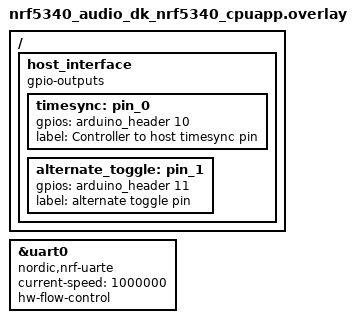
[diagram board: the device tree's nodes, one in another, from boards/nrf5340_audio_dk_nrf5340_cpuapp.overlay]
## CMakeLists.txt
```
# SPDX-License-Identifier: Apache-2.0

cmake_minimum_required(VERSION 3.20.0)

find_package(Zephyr REQUIRED HINTS $ENV{ZEPHYR_BASE})
project(hci_uart)

set(SRCS
    ${CMAKE_CURRENT_SOURCE_DIR}/src/main.c
)

if (CONFIG_ENABLE_AUDIO_TIMESYNC)
    if (CONFIG_SOC_COMPATIBLE_NRF52X)
        target_sources(app PRIVATE src/controller_time_nrf52.c)
    elseif (CONFIG_SOC_COMPATIBLE_NRF5340_CPUAPP)
        target_sources(app PRIVATE src/controller_time_nrf53_app.c)
    elseif (CONFIG_SOC_SERIES_NRF54LX OR CONFIG_SOC_SERIES_NRF54HX)
        target_sources(app PRIVATE src/controller_time_nrf54.c)
    else()
        MESSAGE(FATAL_ERROR "Unsupported series")
    endif()
endif()

target_sources(app PRIVATE ${SRCS})
```

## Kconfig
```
# SPDX-License-Identifier: Apache-2.0

menu "Modules"

config ENABLE_AUDIO_TIMESYNC
    bool "Enables synchronization between the APP and NET core running SD"
    default SOC_SERIES_NRF53X || SOC_NRF52833 || SOC_SERIES_NRF54LX
    select NRFX_RTC0 if SOC_SERIES_NRF53X
    select NRFX_DPPI if SOC_SERIES_NRF53X
    select NRFX_TIMER0 if SOC_SERIES_NRF53X
    select NRFX_RTC2 if SOC_SERIES_NRF52X
    select NRFX_PPI if SOC_SERIES_NRF52X
    select NRFX_TIMER1 if SOC_SERIES_NRF52X
endmenu

module = AUDIO_SYNC_TIMER
module-str = audio-sync-timer

source "subsys/logging/Kconfig.template.log_config"
source "Kconfig.zephyr"
```

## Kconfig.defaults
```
# Audio sync timer
config NRFX_TIMER1
	default y

# Audio sync timer
config NRFX_DPPI
	default y
```

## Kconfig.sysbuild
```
# SPDX-License-Identifier: Apache-2.0

config NRF_DEFAULT_IPC_RADIO
    default y if BOARD_NRF5340DK_NRF5340_CPUAPP || BOARD_NRF5340_AUDIO_DK_NRF5340_CPUAPP || BOARD_THINGY53_NRF5340_CPUAPP || BOARD_THINGY53_NRF5340_CPUAPP_NS || BOARD_NRF54H20DK_NRF54H20_CPUAPP

source "share/sysbuild/Kconfig"
```

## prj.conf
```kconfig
CONFIG_CONSOLE=n
CONFIG_STDOUT_CONSOLE=n
CONFIG_UART_CONSOLE=n
CONFIG_GPIO=y
CONFIG_SERIAL=y
CONFIG_UART_INTERRUPT_DRIVEN=y
CONFIG_BT=y
CONFIG_BT_HCI_RAW=y
CONFIG_BT_HCI_RAW_H4=y
CONFIG_BT_HCI_RAW_H4_ENABLE=y
CONFIG_BT_BUF_ACL_RX_SIZE=255
CONFIG_BT_BUF_CMD_TX_SIZE=255
CONFIG_BT_BUF_EVT_DISCARDABLE_SIZE=255
CONFIG_BT_MAX_CONN=16
#CONFIG_BT_TINYCRYPT_ECC=n

# Setup ISO Buffer
CONFIG_BT_ISO_TX_BUF_COUNT=5
CONFIG_BT_ISO_TX_MTU=251
CONFIG_BT_ISO_RX_BUF_COUNT=5
CONFIG_BT_ISO_RX_MTU=251

# Enable ISO support
CONFIG_BT_ISO_PERIPHERAL=y
CONFIG_BT_ISO_CENTRAL=y
CONFIG_BT_ISO_BROADCASTER=y
CONFIG_BT_ISO_SYNC_RECEIVER=y
CONFIG_BT_EXT_ADV=y
CONFIG_BT_PER_ADV_SYNC_TRANSFER_RECEIVER=y
CONFIG_BT_PER_ADV_SYNC_TRANSFER_SENDER=y

# Support six links as a central, or one link as a peripheral
CONFIG_BT_MAX_CONN=8

# Workaround: Unable to allocate command buffer when using K_NO_WAIT since
# Host number of completed commands does not follow normal flow control.
CONFIG_BT_BUF_CMD_TX_COUNT=10

# for the timesync command
CONFIG_BT_HCI_RAW_CMD_EXT=y
```

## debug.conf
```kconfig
CONFIG_ASSERT=y

#CONFIG_THREAD_NAME=y
#CONFIG_THREAD_ANALYZER=y
#CONFIG_THREAD_ANALYZER_AUTO=y
#CONFIG_THREAD_ANALYZER_RUN_UNLOCKED=y

CONFIG_HW_STACK_PROTECTION=y

CONFIG_CONSOLE=y
CONFIG_LOG=y
CONFIG_LOG_BUFFER_SIZE=4096
CONFIG_RTT_CONSOLE=y
CONFIG_LOG_BACKEND_RTT=y
CONFIG_LOG_BACKEND_RTT_MODE_DROP=n
CONFIG_USE_SEGGER_RTT=y
CONFIG_SEGGER_RTT_BUFFER_SIZE_UP=4096
CONFIG_LOG_BACKEND_SHOW_COLOR=n
CONFIG_LOG_PROCESS_THREAD_STACK_SIZE=1024

CONFIG_LOG_DEFAULT_LEVEL=3

CONFIG_DEBUG_OPTIMIZATIONS=y
CONFIG_DEBUG_INFO=y
```

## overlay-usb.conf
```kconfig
#USB stuff
CONFIG_USB_DEVICE_STACK=y
CONFIG_USB_DEVICE_PRODUCT="Zephyr HCI UART sample"
CONFIG_USB_CDC_ACM=y
CONFIG_USB_DEVICE_INITIALIZE_AT_BOOT=n

#CONFIG_USB_DEVICE_LOG_LEVEL_DBG=y

# stack
#CONFIG_ISR_STACK_SIZE=8192
#CONFIG_IDLE_STACK_SIZE=8192
#CONFIG_MAIN_STACK_SIZE=8192
#CONFIG_SYSTEM_WORKQUEUE_STACK_SIZE=8192
#CONFIG_IPC_SERVICE_BACKEND_RPMSG_WQ_STACK_SIZE=8192
#CONFIG_HEAP_MEM_POOL_SIZE=8192

#debug stuff
#CONFIG_ASSERT=y

#CONFIG_THREAD_NAME=y
#CONFIG_THREAD_ANALYZER=y
#CONFIG_THREAD_ANALYZER_AUTO=y
#CONFIG_THREAD_ANALYZER_RUN_UNLOCKED=y

#CONFIG_HW_STACK_PROTECTION=y

#CONFIG_CONSOLE=n
#CONFIG_LOG=y
#CONFIG_LOG_BUFFER_SIZE=4096
#CONFIG_RTT_CONSOLE=y
#CONFIG_UART_CONSOLE=n
#CONFIG_LOG_BACKEND_RTT=y
#CONFIG_LOG_BACKEND_RTT_MODE_DROP=n
#CONFIG_USE_SEGGER_RTT=y
#CONFIG_SEGGER_RTT_BUFFER_SIZE_UP=2048
#CONFIG_LOG_BACKEND_SHOW_COLOR=n
#CONFIG_LOG_PROCESS_THREAD_STACK_SIZE=8192

#CONFIG_LOG_DEFAULT_LEVEL=3
```

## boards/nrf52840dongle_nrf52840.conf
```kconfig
CONFIG_BOOTLOADER_MCUBOOT=y
```

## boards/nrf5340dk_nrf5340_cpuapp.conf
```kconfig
# timesync
CONFIG_NRFX_TIMER0=y
CONFIG_NRFX_RTC0=y
#CONFIG_NRFX_PPI=y
```

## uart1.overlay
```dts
&gpio_fwd {
    status = "disabled";
};

&uart1 {
    compatible = "nordic,nrf-uarte";
    status = "okay";
    current-speed = <1000000>;
    hw-flow-control;
};

/ {
	chosen {
		zephyr,bt-c2h-uart = &uart1;
	};
};
```

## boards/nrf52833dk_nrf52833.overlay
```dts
/*
 * Copyright (c) 2022 Nordic Semiconductor ASA
 *
 * SPDX-License-Identifier: Apache-2.0
 */

/ {
	host_interface {
		compatible = "gpio-outputs";
		status = "okay";
		timesync: pin_0 {
			gpios = <&gpio1 01 GPIO_ACTIVE_HIGH>;
			label = "Controller to host timesync pin";
		};
	};
};

 &uart0 {
	compatible = "nordic,nrf-uarte";
	current-speed = <1000000>;
	status = "okay";
	hw-flow-control;
};
```

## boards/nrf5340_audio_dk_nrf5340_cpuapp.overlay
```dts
/ {
    host_interface {
        compatible = "gpio-outputs";
        status = "okay";
        timesync: pin_0 {
		    gpios = <&arduino_header 10 GPIO_ACTIVE_HIGH>;
            label = "Controller to host timesync pin";
        };
        alternate_toggle: pin_1 {
		    gpios = <&arduino_header 11 GPIO_ACTIVE_HIGH>;
            label = "alternate toggle pin";
        };
   };
};

&uart0 {
	compatible = "nordic,nrf-uarte";
	current-speed = <1000000>;
	status = "okay";
	hw-flow-control;
};
```

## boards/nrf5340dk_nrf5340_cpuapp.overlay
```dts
/* SPDX-License-Identifier: Apache-2.0 */

/ {
    host_interface {
        compatible = "gpio-outputs";
        status = "okay";
        timesync: pin_0 {
		    gpios = <&arduino_header 10 GPIO_ACTIVE_HIGH>;
            label = "Controller to host timesync pin";
        };
    };
};

&uart0 {
	compatible = "nordic,nrf-uarte";
	current-speed = <1000000>;
	status = "okay";
	hw-flow-control;
};
```

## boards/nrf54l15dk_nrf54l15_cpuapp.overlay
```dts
/*
 * Copyright (c) 2024 Nordic Semiconductor ASA
 *
 * SPDX-License-Identifier: Apache-2.0
 */

/ {
	host_interface {
		compatible = "gpio-outputs";
		status = "okay";
		timesync: pin_0 {
			gpios = <&gpio1 11 GPIO_ACTIVE_HIGH>;
			label = "Controller to host timesync pin";
		};
	};
};

&uart20 {
	compatible = "nordic,nrf-uarte";
	current-speed = <1000000>;
	status = "okay";
	hw-flow-control;
};
```

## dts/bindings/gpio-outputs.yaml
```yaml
description: |
    This is for general gpio support

compatible: "gpio-outputs"

child-binding:
    description: GPIO output child node
    properties:
       gpios:
          type: phandle-array
          required: true
          description: port pin description
       label:
          required: false
          type: string
          description: |
            Human readable string describing the pin. It can be used by an
            application to identify this pin or to retrieve its number/index
            (i.e. child node number) on the parent device.
```

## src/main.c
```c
/*
 * Copyright (c) 2016 Nordic Semiconductor ASA
 * Copyright (c) 2015-2016 Intel Corporation
 *
 * SPDX-License-Identifier: Apache-2.0
 */

#include <errno.h>
#include <stddef.h>
#include <stdio.h>
#include <string.h>

#include <zephyr/kernel.h>
#include <zephyr/arch/cpu.h>
#include <zephyr/sys/byteorder.h>
#include <zephyr/logging/log.h>
#include <zephyr/sys/util.h>

#include <zephyr/device.h>
#include <zephyr/init.h>
#include <zephyr/drivers/uart.h>
//#include <zephyr/drivers/bluetooth/hci_driver.h>
#include <zephyr/drivers/gpio.h>

#include <zephyr/usb/usb_device.h>

#include <zephyr/net_buf.h>
#include <zephyr/bluetooth/bluetooth.h>
#include <zephyr/bluetooth/l2cap.h>
#include <zephyr/bluetooth/hci.h>
#include <zephyr/bluetooth/buf.h>
#include <zephyr/bluetooth/hci_raw.h>

// nRF54L15 - from ncs/nrf/samples/bluetooth/conn_time_sync
#include "controller_time.h"

#define LOG_MODULE_NAME hci_uart
LOG_MODULE_REGISTER(LOG_MODULE_NAME);

static const struct device *const hci_uart_dev =
	DEVICE_DT_GET(DT_CHOSEN(zephyr_bt_c2h_uart));
static K_THREAD_STACK_DEFINE(tx_thread_stack, CONFIG_BT_HCI_TX_STACK_SIZE);
static struct k_thread tx_thread_data;
static K_FIFO_DEFINE(tx_queue);

/* RX in terms of bluetooth communication */
static K_FIFO_DEFINE(uart_tx_queue);

#define H4_CMD 0x01
#define H4_ACL 0x02
#define H4_SCO 0x03
#define H4_EVT 0x04
#define H4_ISO 0x05

/* Receiver states. */
#define ST_IDLE 0	/* Waiting for packet type. */
#define ST_HDR 1	/* Receiving packet header. */
#define ST_PAYLOAD 2	/* Receiving packet payload. */
#define ST_DISCARD 3	/* Dropping packet. */

/* Length of a discard/flush buffer.
 * This is sized to align with a BLE HCI packet:
 * 1 byte H:4 header + 32 bytes ACL/event data
 * Bigger values might overflow the stack since this is declared as a local
 * variable, smaller ones will force the caller to call into discard more
 * often.
 */
#define H4_DISCARD_LEN 33

static int h4_read(const struct device *uart, uint8_t *buf, size_t len)
{
	int rx = uart_fifo_read(uart, buf, len);

	LOG_DBG("read %d req %d", rx, len);

	return rx;
}

static bool valid_type(uint8_t type)
{
	return (type == H4_CMD) | (type == H4_ACL) | (type == H4_ISO);
}

/* Function expects that type is validated and only CMD, ISO or ACL will be used. */
static uint32_t get_len(const uint8_t *hdr_buf, uint8_t type)
{
	switch (type) {
	case H4_CMD:
		return ((const struct bt_hci_cmd_hdr *)hdr_buf)->param_len;
	case H4_ISO:
		return bt_iso_hdr_len(
			sys_le16_to_cpu(((const struct bt_hci_iso_hdr *)hdr_buf)->len));
	case H4_ACL:
		return sys_le16_to_cpu(((const struct bt_hci_acl_hdr *)hdr_buf)->len);
	default:
		LOG_ERR("Invalid type: %u", type);
		return 0;
	}
}

/* Function expects that type is validated and only CMD, ISO or ACL will be used. */
static int hdr_len(uint8_t type)
{
	switch (type) {
	case H4_CMD:
		return sizeof(struct bt_hci_cmd_hdr);
	case H4_ISO:
		return sizeof(struct bt_hci_iso_hdr);
	case H4_ACL:
		return sizeof(struct bt_hci_acl_hdr);
	default:
		LOG_ERR("Invalid type: %u", type);
		return 0;
	}
}

static void rx_isr(void)
{
	static struct net_buf *buf;
	static int remaining;
	static uint8_t state;
	static uint8_t type;
	static uint8_t hdr_buf[MAX(sizeof(struct bt_hci_cmd_hdr),
			sizeof(struct bt_hci_acl_hdr))];
	int read;

	do {
		switch (state) {
		case ST_IDLE:
			/* Get packet type */
			read = h4_read(hci_uart_dev, &type, sizeof(type));
			/* since we read in loop until no data is in the fifo,
			 * it is possible that read = 0.
			 */
			if (read) {
				if (valid_type(type)) {
					/* Get expected header size and switch
					 * to receiving header.
					 */
					remaining = hdr_len(type);
					state = ST_HDR;
				} else {
					LOG_WRN("Unknown header %d", type);
				}
			}
			break;
		case ST_HDR:
			read = h4_read(hci_uart_dev,
				       &hdr_buf[hdr_len(type) - remaining],
				       remaining);
			remaining -= read;
			if (remaining == 0) {
				/* Header received. Allocate buffer and get
				 * payload length. If allocation fails leave
				 * interrupt. On failed allocation state machine
				 * is reset.
				 */
				buf = bt_buf_get_tx(BT_BUF_H4, K_NO_WAIT,
						    &type, sizeof(type));
				if (!buf) {
					LOG_ERR("No available command buffers!");
					state = ST_IDLE;
					return;
				}

				remaining = get_len(hdr_buf, type);

				net_buf_add_mem(buf, hdr_buf, hdr_len(type));
				if (remaining > net_buf_tailroom(buf)) {
					LOG_ERR("Not enough space in buffer");
					net_buf_unref(buf);
					state = ST_DISCARD;
				} else {
					state = ST_PAYLOAD;
				}

			}
			break;
		case ST_PAYLOAD:
			read = h4_read(hci_uart_dev, net_buf_tail(buf),
				       remaining);
			buf->len += read;
			remaining -= read;
			if (remaining == 0) {
				/* Packet received */
				LOG_DBG("putting RX packet in queue.");
				k_fifo_put(&tx_queue, buf);
				state = ST_IDLE;
			}
			break;
		case ST_DISCARD:
		{
			uint8_t discard[H4_DISCARD_LEN];
			size_t to_read = MIN(remaining, sizeof(discard));

			read = h4_read(hci_uart_dev, discard, to_read);
			remaining -= read;
			if (remaining == 0) {
				state = ST_IDLE;
			}

			break;

		}
		default:
			read = 0;
			__ASSERT_NO_MSG(0);
			break;

		}
	} while (read);
}

static void tx_isr(void)
{
	static struct net_buf *buf;
	int len;

	if (!buf) {
		buf = k_fifo_get(&uart_tx_queue, K_NO_WAIT);
		if (!buf) {
			uart_irq_tx_disable(hci_uart_dev);
			return;
		}
	}

	len = uart_fifo_fill(hci_uart_dev, buf->data, buf->len);
	net_buf_pull(buf, len);
	if (!buf->len) {
		net_buf_unref(buf);
		buf = NULL;
	}
}

static void bt_uart_isr(const struct device *unused, void *user_data)
{
	ARG_UNUSED(unused);
	ARG_UNUSED(user_data);

	if (!(uart_irq_rx_ready(hci_uart_dev) ||
	      uart_irq_tx_ready(hci_uart_dev))) {
		LOG_DBG("spurious interrupt");
	}

	if (uart_irq_tx_ready(hci_uart_dev)) {
		tx_isr();
	}

	if (uart_irq_rx_ready(hci_uart_dev)) {
		rx_isr();
	}
}

static void tx_thread(void *p1, void *p2, void *p3)
{
	while (1) {
		struct net_buf *buf;
		int err;

		/* Wait until a buffer is available */
		buf = k_fifo_get(&tx_queue, K_FOREVER);
		/* Pass buffer to the stack */
		err = bt_send(buf);
        if (err!=BT_HCI_ERR_SUCCESS) {
            if (err!=BT_HCI_ERR_EXT_HANDLED) {
                LOG_ERR("Unable to send (err %d)", err);
            }
            net_buf_unref(buf);
        }

		/* Give other threads a chance to run if tx_queue keeps getting
		 * new data all the time.
		 */
		k_yield();
	}
}

static int h4_send(struct net_buf *buf)
{
	LOG_DBG("buf %p type %u len %u", buf, bt_buf_get_type(buf),
		    buf->len);

	k_fifo_put(&uart_tx_queue, buf);
	uart_irq_tx_enable(hci_uart_dev);

	return 0;
}

#if defined(CONFIG_BT_CTLR_ASSERT_HANDLER)
void bt_ctlr_assert_handle(char *file, uint32_t line)
{
	uint32_t len = 0U, pos = 0U;

	/* Disable interrupts, this is unrecoverable */
	(void)irq_lock();

	uart_irq_rx_disable(hci_uart_dev);
	uart_irq_tx_disable(hci_uart_dev);

	if (file) {
		while (file[len] != '\0') {
			if (file[len] == '/') {
				pos = len + 1;
			}
			len++;
		}
		file += pos;
		len -= pos;
	}

	uart_poll_out(hci_uart_dev, H4_EVT);
	/* Vendor-Specific debug event */
	uart_poll_out(hci_uart_dev, 0xff);
	/* 0xAA + strlen + \0 + 32-bit line number */
	uart_poll_out(hci_uart_dev, 1 + len + 1 + 4);
	uart_poll_out(hci_uart_dev, 0xAA);

	if (len) {
		while (*file != '\0') {
			uart_poll_out(hci_uart_dev, *file);
			file++;
		}
		uart_poll_out(hci_uart_dev, 0x00);
	}

	uart_poll_out(hci_uart_dev, line >> 0 & 0xff);
	uart_poll_out(hci_uart_dev, line >> 8 & 0xff);
	uart_poll_out(hci_uart_dev, line >> 16 & 0xff);
	uart_poll_out(hci_uart_dev, line >> 24 & 0xff);

	while (1) {
	}
}
#endif /* CONFIG_BT_CTLR_ASSERT_HANDLER */

static int hci_uart_init(void)
{
	LOG_DBG("");

	if (IS_ENABLED(CONFIG_USB_CDC_ACM)) {
		if (usb_enable(NULL)) {
			LOG_ERR("Failed to enable USB");
			return -EINVAL;
		}
	}

	if (!device_is_ready(hci_uart_dev)) {
		LOG_ERR("HCI UART %s is not ready", hci_uart_dev->name);
		return -EINVAL;
	}

	uart_irq_rx_disable(hci_uart_dev);
	uart_irq_tx_disable(hci_uart_dev);

	uart_irq_callback_set(hci_uart_dev, bt_uart_isr);

	uart_irq_rx_enable(hci_uart_dev);

	return 0;
}

SYS_INIT(hci_uart_init, APPLICATION, CONFIG_KERNEL_INIT_PRIORITY_DEVICE);

#if defined(CONFIG_ENABLE_AUDIO_TIMESYNC)

#define TIMESYNC_GPIO  DT_NODELABEL(timesync)

#if DT_NODE_HAS_STATUS(TIMESYNC_GPIO, okay)
static const struct gpio_dt_spec timesync_pin = GPIO_DT_SPEC_GET(TIMESYNC_GPIO, gpios);
#else
#error "No timesync gpio available!"
#endif

#define  HCI_CMD_ISO_TIMESYNC	(0x200)

struct hci_cmd_iso_timestamp_response {
    struct bt_hci_evt_cc_status cc;
    uint32_t timestamp;
} __packed;

uint8_t hci_cmd_iso_timesync_cb(struct net_buf *buf)
{
	struct net_buf *rsp;
    struct hci_cmd_iso_timestamp_response *response;

	LOG_INF("buf %p type %u len %u", buf, bt_buf_get_type(buf), buf->len);
	LOG_INF("buf[0] = 0x%02x", buf->data[0]);

	uint32_t timestamp_second_us = 0;

	// Lock interrupts to avoid interrupt between time capture and gpio toggle
	uint32_t key = arch_irq_lock();

#if defined(CONFIG_SOC_SERIES_NRF54LX) || defined(CONFIG_SOC_SERIES_NRF52X) || defined(CONFIG_SOC_SERIES_NRF53X)
	timestamp_second_us = (uint32_t) controller_time_us_get();
#else
    #error selected SoC is not supported yet
#endif

#if DT_NODE_HAS_STATUS(TIMESYNC_GPIO, okay)
	// raise
	gpio_pin_set_dt( &timesync_pin, 1 );
#endif

	// Unlock interrupts
	arch_irq_unlock(key);

	// emit event
	rsp = bt_hci_cmd_complete_create(BT_OP(BT_OGF_VS, HCI_CMD_ISO_TIMESYNC), sizeof(*response));
	response = net_buf_add(rsp, sizeof(*response));
	response->cc.status = BT_HCI_ERR_SUCCESS;
	response->timestamp = timestamp_second_us;

	if (IS_ENABLED(CONFIG_BT_HCI_RAW_H4)) {
		net_buf_push_u8(rsp, H4_EVT);
	}

    h4_send( rsp );

#if DT_NODE_HAS_STATUS(TIMESYNC_GPIO, okay)
	gpio_pin_set_dt( &timesync_pin, 0 );
#endif

	return BT_HCI_ERR_EXT_HANDLED;
}
#endif

int main(void)
{
	/* incoming events and data from the controller */
	static K_FIFO_DEFINE(rx_queue);
	int err;

	LOG_DBG("Start");
	__ASSERT(hci_uart_dev, "UART device is NULL");

	/* Enable the raw interface, this will in turn open the HCI driver */
	bt_enable_raw(&rx_queue);

	if (IS_ENABLED(CONFIG_BT_WAIT_NOP)) {
		/* Issue a Command Complete with NOP */
		int i;

		const struct {
			const uint8_t h4;
			const struct bt_hci_evt_hdr hdr;
			const struct bt_hci_evt_cmd_complete cc;
		} __packed cc_evt = {
			.h4 = H4_EVT,
			.hdr = {
				.evt = BT_HCI_EVT_CMD_COMPLETE,
				.len = sizeof(struct bt_hci_evt_cmd_complete),
			},
			.cc = {
				.ncmd = 1,
				.opcode = sys_cpu_to_le16(BT_OP_NOP),
			},
		};

		for (i = 0; i < sizeof(cc_evt); i++) {
			uart_poll_out(hci_uart_dev,
				      *(((const uint8_t *)&cc_evt)+i));
		}
	}

#if defined(CONFIG_ENABLE_AUDIO_TIMESYNC)
	/* Register iso_timesync command */
	static struct bt_hci_raw_cmd_ext cmd_list = {
	    .op = BT_OP(BT_OGF_VS, HCI_CMD_ISO_TIMESYNC),
		.min_len = 1,
		.func = hci_cmd_iso_timesync_cb
	};

#if DT_NODE_HAS_STATUS(TIMESYNC_GPIO, okay)
	gpio_pin_configure_dt(&timesync_pin, GPIO_OUTPUT_INACTIVE);
#endif

	bt_hci_raw_cmd_ext_register(&cmd_list, 1);
#endif

	/* Spawn the TX thread and start feeding commands and data to the
	 * controller
	 */
	k_thread_create(&tx_thread_data, tx_thread_stack,
			K_THREAD_STACK_SIZEOF(tx_thread_stack), tx_thread,
			NULL, NULL, NULL, K_PRIO_COOP(7), 0, K_NO_WAIT);
	k_thread_name_set(&tx_thread_data, "HCI uart TX");

#if 0
    while (1) {
		uint8_t c = 'A';
		uart_fifo_fill(hci_uart_dev, &c, 1);
		uart_irq_tx_enable(hci_uart_dev);
		k_sleep( K_MSEC(100) );
	}
    return 0;
#endif

    while (1) {
		struct net_buf *buf;

		buf = k_fifo_get(&rx_queue, K_FOREVER);
		err = h4_send(buf);
		if (err) {
			LOG_ERR("Failed to send");
		}
	}
	return 0;
}
```

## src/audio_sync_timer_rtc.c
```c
/*
 * Copyright (c) 2023 Nordic Semiconductor ASA
 *
 * SPDX-License-Identifier: LicenseRef-Nordic-5-Clause
 */

#include "audio_sync_timer.h"

#include <zephyr/kernel.h>
#include <zephyr/init.h>
#include <nrfx_dppi.h>
#include <nrfx_ipc.h>
#include <nrfx_rtc.h>
#include <nrfx_timer.h>
#include <nrfx_egu.h>

#include <zephyr/logging/log.h>
LOG_MODULE_REGISTER(audio_sync_timer, CONFIG_AUDIO_SYNC_TIMER_LOG_LEVEL);

#define AUDIO_SYNC_TIMER_NET_APP_IPC_EVT_CHANNEL                4
#define AUDIO_SYNC_TIMER_NET_APP_IPC_EVT                        NRF_IPC_EVENT_RECEIVE_4

#define AUDIO_SYNC_HF_TIMER_INSTANCE_NUMBER                     1

#define AUDIO_SYNC_HF_TIMER_CURR_TIME_CAPTURE_CHANNEL           1
#define AUDIO_SYNC_HF_TIMER_CURR_TIME_CAPTURE                   NRF_TIMER_TASK_CAPTURE1

static const nrfx_timer_t audio_sync_hf_timer_instance =
	NRFX_TIMER_INSTANCE(AUDIO_SYNC_HF_TIMER_INSTANCE_NUMBER);

#define AUDIO_SYNC_LF_TIMER_INSTANCE_NUMBER                     0

#define AUDIO_SYNC_LF_TIMER_CURR_TIME_CAPTURE_CHANNEL           1
#define AUDIO_SYNC_LF_TIMER_CURR_TIME_CAPTURE                   NRF_RTC_TASK_CAPTURE_1

static uint8_t dppi_channel_curr_time_capture;

static const nrfx_rtc_config_t rtc_cfg = NRFX_RTC_DEFAULT_CONFIG;

static const nrfx_rtc_t audio_sync_lf_timer_instance =
	NRFX_RTC_INSTANCE(AUDIO_SYNC_LF_TIMER_INSTANCE_NUMBER);

static uint8_t dppi_channel_timer_sync_with_rtc;
static uint8_t dppi_channel_rtc_start;
static volatile uint32_t num_rtc_overflows;

static nrfx_timer_config_t cfg = {.frequency = NRFX_MHZ_TO_HZ(1UL),
				  .mode = NRF_TIMER_MODE_TIMER,
				  .bit_width = NRF_TIMER_BIT_WIDTH_32,
				  .interrupt_priority = NRFX_TIMER_DEFAULT_CONFIG_IRQ_PRIORITY,
				  .p_context = NULL};

static uint32_t timestamp_from_rtc_and_timer_get(uint32_t ticks, uint32_t remainder_us)
{
	const uint64_t rtc_ticks_in_femto_units = 30517578125UL;
	const uint32_t rtc_overflow_time_us = 512000000UL;

	return ((ticks * rtc_ticks_in_femto_units) / 1000000000UL) +
		(num_rtc_overflows * rtc_overflow_time_us) +
		remainder_us;
}

uint32_t audio_sync_timer_capture(void)
{
	/* Ensure that the follow product specification statement is handled:
	 *
	 * There is a delay of 6 PCLK16M periods from when the TASKS_CAPTURE[n] is triggered
	 * until the corresponding CC[n] register is updated.
	 *
	 * Lets have a stale value in the CC[n] register and compare that it is different when
	 * we capture using DPPI.
	 *
	 * We ensure it is stale by setting it as the previous tick relative to current
	 * counter value.
	 */
	uint32_t tick_stale = nrf_rtc_counter_get(audio_sync_lf_timer_instance.p_reg);

	/* Set a stale value in the CC[n] register */
	tick_stale--;
	nrf_rtc_cc_set(audio_sync_lf_timer_instance.p_reg,
		       AUDIO_SYNC_LF_TIMER_CURR_TIME_CAPTURE_CHANNEL, tick_stale);

	/* Trigger EGU task to capture RTC and TIMER value */
	nrf_egu_task_trigger(NRF_EGU0, NRF_EGU_TASK_TRIGGER0);

	/* Read captured RTC value */
	uint32_t tick = nrf_rtc_cc_get(audio_sync_lf_timer_instance.p_reg,
				       AUDIO_SYNC_LF_TIMER_CURR_TIME_CAPTURE_CHANNEL);

	/* If required, wait until CC[n] register is updated */
	while (tick == tick_stale) {
		tick = nrf_rtc_cc_get(audio_sync_lf_timer_instance.p_reg,
				      AUDIO_SYNC_LF_TIMER_CURR_TIME_CAPTURE_CHANNEL);
	}

	/* Read captured TIMER value */
	uint32_t remainder_us = nrf_timer_cc_get(NRF_TIMER1,
						 AUDIO_SYNC_HF_TIMER_CURR_TIME_CAPTURE_CHANNEL);

	return timestamp_from_rtc_and_timer_get(tick, remainder_us);
}


//#include <stdio.h>
//#include "led.h"

//bool led_status = false;
static void unused_timer_isr_handler(nrf_timer_event_t event_type, void *p_context)
{
	ARG_UNUSED(event_type);
	ARG_UNUSED(p_context);
#if 0
    if(event_type == NRF_TIMER_EVENT_COMPARE2)
    {
        if( led_status ){
            led_off( LED_APP_3_GREEN );
            led_status = false;
        } else {
            led_on( LED_APP_3_GREEN );
            led_status = true;
        }
//        char * p_msg = p_context;
//        uint32_t remainder_us = nrf_timer_cc_get(NRF_TIMER1,
//						 AUDIO_SYNC_HF_TIMER_CURR_TIME_CAPTURE_CHANNEL);
//        LOG_INF("%d\n", remainder_us );
//        printf("Timer finished. Context passed to the handler: >%s<", p_msg);
    }
#endif
}

static void rtc_isr_handler(nrfx_rtc_int_type_t int_type)
{
	if (int_type == NRFX_RTC_INT_OVERFLOW) {
		num_rtc_overflows++;
	}
}

/**
 * @brief Initialize audio sync timer
 *
 * @note The audio sync timers is replicating the controller's clock.
 * The controller starts or clears the sync timer using a PPI signal
 * sent from the controller. This makes the two clocks synchronized.
 *
 * @return 0 if successful, error otherwise
 */
static int audio_sync_timer_init(void)
{
	nrfx_err_t ret;

	ret = nrfx_timer_init(&audio_sync_hf_timer_instance, &cfg, unused_timer_isr_handler);
	if (ret - NRFX_ERROR_BASE_NUM) {
		LOG_ERR("nrfx timer init error: %d", ret);
		return -ENODEV;
	}

	ret = nrfx_rtc_init(&audio_sync_lf_timer_instance, &rtc_cfg, rtc_isr_handler);
	if (ret - NRFX_ERROR_BASE_NUM) {
		LOG_ERR("nrfx rtc init error: %d", ret);
		return -ENODEV;
	}

	IRQ_CONNECT(RTC0_IRQn, IRQ_PRIO_LOWEST, nrfx_rtc_0_irq_handler, NULL, 0);
	nrfx_rtc_overflow_enable(&audio_sync_lf_timer_instance, true);

	/* Initialize capturing of current timestamps */
	ret = nrfx_dppi_channel_alloc(&dppi_channel_curr_time_capture);
	if (ret - NRFX_ERROR_BASE_NUM) {
		LOG_ERR("nrfx DPPI channel alloc error (current time capture) - Return value: %d", ret);
		return -ENOMEM;
	}

	nrf_rtc_subscribe_set(audio_sync_lf_timer_instance.p_reg,
			      AUDIO_SYNC_LF_TIMER_CURR_TIME_CAPTURE,
			      dppi_channel_curr_time_capture);

	nrf_timer_subscribe_set(audio_sync_hf_timer_instance.p_reg,
				AUDIO_SYNC_HF_TIMER_CURR_TIME_CAPTURE,
				dppi_channel_curr_time_capture);

	nrf_egu_publish_set(NRF_EGU0, NRF_EGU_EVENT_TRIGGERED0, dppi_channel_curr_time_capture);

	ret = nrfx_dppi_channel_enable(dppi_channel_curr_time_capture);
	if (ret - NRFX_ERROR_BASE_NUM) {
		LOG_ERR("nrfx DPPI channel enable error (current time capture) - Return value: %d", ret);
		return -EIO;
	}

	/* Initialize functionality for synchronization between APP and NET core */
	ret = nrfx_dppi_channel_alloc(&dppi_channel_rtc_start);
	if (ret - NRFX_ERROR_BASE_NUM) {
		LOG_ERR("nrfx DPPI channel alloc error (timer clear): %d", ret);
		return -ENOMEM;
	}

	nrf_rtc_subscribe_set(audio_sync_lf_timer_instance.p_reg, NRF_RTC_TASK_CLEAR,
			      dppi_channel_rtc_start);
	nrf_timer_subscribe_set(audio_sync_hf_timer_instance.p_reg, NRF_TIMER_TASK_START,
				dppi_channel_rtc_start);

	nrf_ipc_receive_config_set(NRF_IPC, AUDIO_SYNC_TIMER_NET_APP_IPC_EVT_CHANNEL,
				   NRF_IPC_CHANNEL_4);
	nrf_ipc_publish_set(NRF_IPC, AUDIO_SYNC_TIMER_NET_APP_IPC_EVT, dppi_channel_rtc_start);

	ret = nrfx_dppi_channel_enable(dppi_channel_rtc_start);
	if (ret - NRFX_ERROR_BASE_NUM) {
		LOG_ERR("nrfx DPPI channel enable error (timer clear): %d", ret);
		return -EIO;
	}

	/* Initialize functionality for synchronization between RTC and TIMER */
	ret = nrfx_dppi_channel_alloc(&dppi_channel_timer_sync_with_rtc);
	if (ret - NRFX_ERROR_BASE_NUM) {
		LOG_ERR("nrfx DPPI channel alloc error (timer clear): %d", ret);
		return -ENOMEM;
	}

	nrf_rtc_publish_set(audio_sync_lf_timer_instance.p_reg, NRF_RTC_EVENT_TICK,
			    dppi_channel_timer_sync_with_rtc);
	nrf_timer_subscribe_set(audio_sync_hf_timer_instance.p_reg, NRF_TIMER_TASK_CLEAR,
				dppi_channel_timer_sync_with_rtc);

	nrfx_rtc_tick_enable(&audio_sync_lf_timer_instance, false);

	ret = nrfx_dppi_channel_enable(dppi_channel_timer_sync_with_rtc);
	if (ret - NRFX_ERROR_BASE_NUM) {
		LOG_ERR("nrfx DPPI channel enable error (timer clear): %d", ret);
		return -EIO;
	}

	nrfx_rtc_enable(&audio_sync_lf_timer_instance);

    LOG_DBG("Audio sync timer initialized");
	return 0;
}

SYS_INIT(audio_sync_timer_init, POST_KERNEL, CONFIG_KERNEL_INIT_PRIORITY_DEFAULT);
```

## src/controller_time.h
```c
/*
 * Copyright (c) 2024 Nordic Semiconductor ASA
 *
 * SPDX-License-Identifier: LicenseRef-Nordic-5-Clause
 */

// BK: based on / taken from ncs/nrf/samples/bluetooth/conn_time_sync/src/controller_time_sync.h

#ifndef CONTROLLER_TIME_SYNC_H__
#define CONTROLLER_TIME_SYNC_H__

#include <stdint.h>
#include <stdbool.h>
#include <zephyr/kernel.h>

/** @brief Obtain the current Bluetooth controller time.
 *
 * The timestamps are based upon this clock.
 *
 * @return The current controller time.
 */
uint64_t controller_time_us_get(void);

/** @brief Set the controller to trigger a PPI event at the given timestamp.
 *
 * @param timestamp_us The timestamp where it will trigger.
 */
void controller_time_trigger_set(uint64_t timestamp_us);

/** @brief Get the address of the event that will trigger.
 *
 * @return The address of the event that will trigger.
 */
uint32_t controller_time_trigger_event_addr_get(void);

#endif

/**
 * @}
 */
```

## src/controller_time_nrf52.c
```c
/*
 * Copyright (c) 2024 Nordic Semiconductor ASA
 *
 * SPDX-License-Identifier: LicenseRef-Nordic-5-Clause
 */

/** This file implements controller time management for 52 Series devices
 *
 * As the controller clock is not directly accessible, the controller
 * time is obtained using a mirrored RTC peripheral.
 * To achieve microsecond accurate toggling, a timer peripheral is also used.
 */

// BK: taken from ncs/nrf/samples/bluetooth/conn_time_sync/src/controller_time_nrf52.c

#include <zephyr/kernel.h>
#include <zephyr/sys/barrier.h>
#include <mpsl_clock.h>
#include <nrfx_rtc.h>
#include <nrfx_timer.h>
#include <helpers/nrfx_gppi.h>
#include <hal/nrf_egu.h>
#include <soc.h>
#include "controller_time.h"

static const nrfx_rtc_t app_rtc_instance = NRFX_RTC_INSTANCE(2);
static const nrfx_timer_t app_timer_instance = NRFX_TIMER_INSTANCE(1);

static uint8_t ppi_chan_on_rtc_match;
static volatile uint32_t num_rtc_overflows;

static uint32_t offset_ticks_and_controller_to_app_rtc;

static void rtc_isr_handler(nrfx_rtc_int_type_t int_type)
{
	if (int_type == NRFX_RTC_INT_OVERFLOW) {
		num_rtc_overflows++;
	}
}

static void unused_timer_isr_handler(nrf_timer_event_t event_type, void *ctx)
{
	ARG_UNUSED(event_type);
	ARG_UNUSED(ctx);
}

static int32_t rtc_diff_get(void)
{
	uint32_t controller_ticks = nrf_rtc_counter_get(NRF_RTC0);
	uint32_t app_ticks = nrf_rtc_counter_get(app_rtc_instance.p_reg);

	return controller_ticks - app_ticks;
}

static int rtc_config(void)
{
	int ret;

	const nrfx_rtc_config_t rtc_cfg = NRFX_RTC_DEFAULT_CONFIG;

	ret = nrfx_rtc_init(&app_rtc_instance, &rtc_cfg, rtc_isr_handler);
	if (ret != NRFX_SUCCESS) {
		printk("Failed initializing RTC (ret: %d)\n", ret - NRFX_ERROR_BASE_NUM);
		return -ENODEV;
	}

#ifndef BT_CTLR_SDC_BSIM_BUILD
	IRQ_CONNECT(NRFX_IRQ_NUMBER_GET(NRF_RTC_INST_GET(2)), IRQ_PRIO_LOWEST,
		    NRFX_RTC_INST_HANDLER_GET(2), NULL, 0);
#else
	IRQ_CONNECT(NRFX_IRQ_NUMBER_GET(NRF_RTC_INST_GET(2)), 0,
		    (void *)NRFX_RTC_INST_HANDLER_GET(2), NULL, 0);
#endif

	nrfx_rtc_overflow_enable(&app_rtc_instance, true);
	nrfx_rtc_tick_enable(&app_rtc_instance, false);
	nrfx_rtc_enable(&app_rtc_instance);

	/* To obtain the controller timestamp without modifying the state of RTC0,
	 * we find the offset between RTC0 and our mirrored RTC.
	 * We achieve this by reading out the counter value of both of them.
	 * When the diff between those two have been equal twice, we know the
	 * time difference in ticks.
	 */

	uint32_t sync_attempts = 10;

	while (sync_attempts > 0) {
		sync_attempts--;

		int32_t diff_measurement_1 = rtc_diff_get();

		/* We need to wait half an RTC tick to ensure we are not measuring
		 * the diff between the two RTCs at the point in time where their
		 * values are transitioning.
		 */
		k_busy_wait(15);

		int32_t diff_measurement_2 = rtc_diff_get();

		if (diff_measurement_1 == diff_measurement_2) {
			offset_ticks_and_controller_to_app_rtc = diff_measurement_1;
			return 0;
		}
	}

	printk("Controller time sync failure\n");
	offset_ticks_and_controller_to_app_rtc = 0;
	return -EINVAL;
}

static int timer_config(void)
{
	int ret;
	uint8_t ppi_chan_timer_clear_on_rtc_tick;
	const nrfx_timer_config_t timer_cfg = {
		.frequency = NRFX_MHZ_TO_HZ(1UL),
		.mode = NRF_TIMER_MODE_TIMER,
		.bit_width = NRF_TIMER_BIT_WIDTH_8,
		.interrupt_priority = NRFX_TIMER_DEFAULT_CONFIG_IRQ_PRIORITY,
		.p_context = NULL};

	ret = nrfx_timer_init(&app_timer_instance, &timer_cfg, unused_timer_isr_handler);
	if (ret != NRFX_SUCCESS) {
		printk("Failed initializing timer (ret: %d)\n", ret - NRFX_ERROR_BASE_NUM);
		return -ENODEV;
	}

	/* Clear the TIMER every RTC tick. */
	if (nrfx_gppi_channel_alloc(&ppi_chan_timer_clear_on_rtc_tick) != NRFX_SUCCESS) {
		printk("Failed allocating for clearing TIMER on RTC TICK\n");
		return -ENOMEM;
	}

	nrfx_gppi_channel_endpoints_setup(ppi_chan_timer_clear_on_rtc_tick,
					  nrfx_rtc_event_address_get(&app_rtc_instance,
								     NRF_RTC_EVENT_TICK),
					  nrfx_timer_task_address_get(&app_timer_instance,
								      NRF_TIMER_TASK_CLEAR));

	nrfx_gppi_channels_enable(BIT(ppi_chan_timer_clear_on_rtc_tick));

	nrfx_timer_enable(&app_timer_instance);

	return 0;
}

/** Configure the TIMER and RTC in such a way that microsecond accurate timing can be achieved.
 *
 * To get microsecond accurate toggling, we need to combine both the RTC and TIMER peripheral.
 * That is, both a RTC CC value and TIMER CC value needs to be set.
 * We should only trigger an EGU task when the TIMER CC value matches after the
 * RTC CC value matched.
 * This is achieved using a PPI group. The group is enabled when the RTC CC matches and disabled
 * again then the TIMER CC matches.
 */
int config_egu_trigger_on_rtc_and_timer_match(void)
{
	uint8_t ppi_chan_on_timer_match;

	if (nrfx_gppi_channel_alloc(&ppi_chan_on_rtc_match) != NRFX_SUCCESS) {
		printk("Failed allocating for RTC match\n");
		return -ENOMEM;
	}

	if (nrfx_gppi_channel_alloc(&ppi_chan_on_timer_match) != NRFX_SUCCESS) {
		printk("Failed allocating for TIMER match\n");
		return -ENOMEM;
	}

	nrfx_gppi_group_clear(NRFX_GPPI_CHANNEL_GROUP0);
	nrfx_gppi_group_disable(NRFX_GPPI_CHANNEL_GROUP0);
	nrfx_gppi_channels_include_in_group(
		BIT(ppi_chan_on_timer_match) | BIT(ppi_chan_on_rtc_match),
		NRFX_GPPI_CHANNEL_GROUP0);

	nrfx_gppi_channel_endpoints_setup(ppi_chan_on_rtc_match,
					  nrfx_rtc_event_address_get(&app_rtc_instance,
								     NRF_RTC_EVENT_COMPARE_0),
					  nrfx_gppi_task_address_get(NRFX_GPPI_TASK_CHG0_EN));

	nrfx_gppi_channel_endpoints_setup(ppi_chan_on_timer_match,
					  nrfx_timer_event_address_get(&app_timer_instance,
								       NRF_TIMER_EVENT_COMPARE0),
					  nrf_egu_task_address_get(NRF_EGU0,
								   NRF_EGU_TASK_TRIGGER0));
	nrfx_gppi_fork_endpoint_setup(ppi_chan_on_timer_match,
				      nrfx_gppi_task_address_get(NRFX_GPPI_TASK_CHG0_DIS));

	return 0;
}

int controller_time_init(void)
{
	int ret;

	ret = rtc_config();
	if (ret) {
		return ret;
	}

	ret = timer_config();
	if (ret) {
		return ret;
	}

	return config_egu_trigger_on_rtc_and_timer_match();
}

static uint64_t rtc_ticks_to_us(uint32_t rtc_ticks)
{
	const uint64_t rtc_ticks_in_femto_units = 30517578125UL;

	return (rtc_ticks * rtc_ticks_in_femto_units) / 1000000000UL;
}

static uint32_t us_to_rtc_ticks(uint32_t timestamp_us)
{
	const uint64_t rtc_ticks_in_femto_units = 30517578125UL;

	return ((uint64_t)(timestamp_us) * 1000000000UL) / rtc_ticks_in_femto_units;
}

uint64_t controller_time_us_get(void)
{
	const uint64_t rtc_overflow_time_us = 512000000UL;

	/* On the 52 series the RTC has to task to capture the current RTC value.
	 * Therefore we cannot capture the TIMER and RTC value simultaneously.
	 * Therefore we only use the RTC to read out the current time here.
	 * This will result in an error of maximum one RTC tick.
	 */

	uint32_t captured_rtc_overflows;
	uint32_t captured_rtc_ticks;

	while (true) {
		captured_rtc_overflows = num_rtc_overflows;

		/* Read out RTC ticks after reading number of overflows. */
		barrier_isync_fence_full();

		captured_rtc_ticks = nrf_rtc_counter_get(app_rtc_instance.p_reg);

		/* Read out number of overflows after reading number of RTC ticks  */
		barrier_isync_fence_full();

		if (captured_rtc_overflows == num_rtc_overflows) {
			/* There were no new overflows after reading ticks.
			 * That is, we can use the captured value.
			 */
			break;
		}
	}

	return rtc_ticks_to_us(captured_rtc_ticks) +
	       (captured_rtc_overflows * rtc_overflow_time_us) +
	       rtc_ticks_to_us(offset_ticks_and_controller_to_app_rtc);
}

void controller_time_trigger_set(uint64_t timestamp_us)
{
	uint64_t timestamp_without_rtc_offset =
		timestamp_us - rtc_ticks_to_us(offset_ticks_and_controller_to_app_rtc);

	uint32_t num_overflows = timestamp_without_rtc_offset / 512000000UL;
	uint64_t overflow_time_us = num_overflows * 512000000UL;

	uint32_t rtc_remainder_time_us = timestamp_without_rtc_offset - overflow_time_us;
	uint32_t rtc_val = us_to_rtc_ticks(rtc_remainder_time_us);
	uint8_t timer_val =	timestamp_without_rtc_offset - rtc_ticks_to_us(rtc_val);

	/* Ensure the timer value lies between 1 and 30 so that it will
	 * always be between two RTC ticks.
	 */
	timer_val = MAX(timer_val, 1);
	timer_val = MIN(timer_val, 30);

	if (nrfx_rtc_cc_set(&app_rtc_instance, 0, rtc_val, false) != NRFX_SUCCESS) {
		printk("Failed setting trigger\n");
	}

	nrfx_timer_compare(&app_timer_instance, 0, timer_val, false);
	nrfx_gppi_channels_enable(BIT(ppi_chan_on_rtc_match));
}

uint32_t controller_time_trigger_event_addr_get(void)
{
	return nrf_egu_event_address_get(NRF_EGU0, NRF_EGU_EVENT_TRIGGERED0);
}

SYS_INIT(controller_time_init, POST_KERNEL, CONFIG_KERNEL_INIT_PRIORITY_DEFAULT);
```

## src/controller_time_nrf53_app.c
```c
/*
 * Copyright (c) 2024 Nordic Semiconductor ASA
 *
 * SPDX-License-Identifier: LicenseRef-Nordic-5-Clause
 */

/** This file implements controller time management for 53 Series devices
 *
 * As the controller clock is not directly accessible, the controller
 * time is obtained using a mirrored RTC peripheral.
 * The RTC is started upon starting the controller clock on the network core.
 * To achieve microsecond accurate toggling, a timer peripheral is also used.
 */

// BK: taken from ncs/nrf/samples/bluetooth/conn_time_sync/src/controller_time_nrf53_app.c
// - we already have a similar code in audio_sync_timer_rtc.c from nrf5340_audio

#include <zephyr/kernel.h>
#include <zephyr/init.h>
#include <zephyr/sys/barrier.h>
#include <helpers/nrfx_gppi.h>
#include <nrfx_rtc.h>
#include <nrfx_timer.h>
#include <hal/nrf_ipc.h>
#include <hal/nrf_egu.h>
#include "controller_time.h"

static const nrfx_rtc_t app_rtc_instance = NRFX_RTC_INSTANCE(0);
static const nrfx_timer_t app_timer_instance = NRFX_TIMER_INSTANCE(0);

static uint8_t ppi_chan_on_rtc_match;
static volatile uint32_t num_rtc_overflows;

static void rtc_isr_handler(nrfx_rtc_int_type_t int_type)
{
	if (int_type == NRFX_RTC_INT_OVERFLOW) {
		num_rtc_overflows++;
	}
}

static void unused_timer_isr_handler(nrf_timer_event_t event_type, void *ctx)
{
	ARG_UNUSED(event_type);
	ARG_UNUSED(ctx);
}

static int rtc_config(void)
{
	int ret;
	uint8_t dppi_channel_rtc_start;
	const nrfx_rtc_config_t rtc_cfg = NRFX_RTC_DEFAULT_CONFIG;

	ret = nrfx_rtc_init(&app_rtc_instance, &rtc_cfg, rtc_isr_handler);
	if (ret != NRFX_SUCCESS) {
		printk("Failed initializing RTC (ret: %d)\n", ret - NRFX_ERROR_BASE_NUM);
		return -ENODEV;
	}

#ifndef BT_CTLR_SDC_BSIM_BUILD
	IRQ_CONNECT(NRFX_IRQ_NUMBER_GET(NRF_RTC_INST_GET(0)), IRQ_PRIO_LOWEST,
		    NRFX_RTC_INST_HANDLER_GET(0), NULL, 0);
#else
	IRQ_CONNECT(NRFX_IRQ_NUMBER_GET(NRF_RTC_INST_GET(0)), 0,
		    (void *)NRFX_RTC_INST_HANDLER_GET(0), NULL, 0);
#endif

	nrfx_rtc_overflow_enable(&app_rtc_instance, true);
	nrfx_rtc_tick_enable(&app_rtc_instance, false);
	nrfx_rtc_enable(&app_rtc_instance);


	/* The application core RTC is started synchronously with the controller
	 * RTC using PPI over IPC.
	 */
	ret = nrfx_gppi_channel_alloc(&dppi_channel_rtc_start);
	if (ret != NRFX_SUCCESS) {
		printk("nrfx DPPI channel alloc error for starting RTC: %d", ret);
		return -ENODEV;
	}

	nrf_ipc_receive_config_set(NRF_IPC, 4, NRF_IPC_CHANNEL_4);

	nrfx_gppi_channel_endpoints_setup(dppi_channel_rtc_start,
					  nrfx_rtc_task_address_get(&app_rtc_instance,
								     NRF_RTC_TASK_CLEAR),
					  nrf_ipc_event_address_get(NRF_IPC,
								    NRF_IPC_EVENT_RECEIVE_4));

	nrfx_gppi_channels_enable(BIT(dppi_channel_rtc_start));

	return 0;
}

static int timer_config(void)
{
	int ret;
	uint8_t ppi_chan_timer_clear_on_rtc_tick;
	const nrfx_timer_config_t timer_cfg = {
		.frequency = NRFX_MHZ_TO_HZ(1UL),
		.mode = NRF_TIMER_MODE_TIMER,
		.bit_width = NRF_TIMER_BIT_WIDTH_8,
		.interrupt_priority = NRFX_TIMER_DEFAULT_CONFIG_IRQ_PRIORITY,
		.p_context = NULL};

	ret = nrfx_timer_init(&app_timer_instance, &timer_cfg, unused_timer_isr_handler);
	if (ret != NRFX_SUCCESS) {
		printk("Failed initializing timer (ret: %d)\n", ret - NRFX_ERROR_BASE_NUM);
		return -ENODEV;
	}

	/* Clear the TIMER every RTC tick. */
	if (nrfx_gppi_channel_alloc(&ppi_chan_timer_clear_on_rtc_tick) != NRFX_SUCCESS) {
		printk("Failed allocating for clearing TIMER on RTC TICK\n");
		return -ENOMEM;
	}

	nrfx_gppi_channel_endpoints_setup(ppi_chan_timer_clear_on_rtc_tick,
					  nrfx_rtc_event_address_get(&app_rtc_instance,
								     NRF_RTC_EVENT_TICK),
					  nrfx_timer_task_address_get(&app_timer_instance,
								      NRF_TIMER_TASK_CLEAR));

	nrfx_gppi_channels_enable(BIT(ppi_chan_timer_clear_on_rtc_tick));

	nrfx_timer_enable(&app_timer_instance);

	return 0;
}

/** Configure the TIMER and RTC in such a way that microsecond accurate timing can be achieved.
 *
 * To get microsecond accurate toggling, we need to combine both the RTC and TIMER peripheral.
 * That is, both a RTC CC value and TIMER CC value needs to be set.
 * We should only trigger an EGU task when the TIMER CC value
 * matches after the RTC CC value matched.
 * This is achieved using a PPI group. The group is enabled when the RTC CC matches and disabled
 * again then the TIMER CC matches.
 */
int config_egu_trigger_on_rtc_and_timer_match(void)
{
	uint8_t ppi_chan_on_timer_match;

	if (nrfx_gppi_channel_alloc(&ppi_chan_on_rtc_match) != NRFX_SUCCESS) {
		printk("Failed allocating for RTC match\n");
		return -ENOMEM;
	}

	if (nrfx_gppi_channel_alloc(&ppi_chan_on_timer_match) != NRFX_SUCCESS) {
		printk("Failed allocating for TIMER match\n");
		return -ENOMEM;
	}

	nrfx_gppi_group_clear(NRFX_GPPI_CHANNEL_GROUP0);
	nrfx_gppi_group_disable(NRFX_GPPI_CHANNEL_GROUP0);
	nrfx_gppi_channels_include_in_group(
		BIT(ppi_chan_on_timer_match) | BIT(ppi_chan_on_rtc_match),
		NRFX_GPPI_CHANNEL_GROUP0);

	nrfx_gppi_channel_endpoints_setup(ppi_chan_on_rtc_match,
					  nrfx_rtc_event_address_get(&app_rtc_instance,
								     NRF_RTC_EVENT_COMPARE_0),
					  nrfx_gppi_task_address_get(NRFX_GPPI_TASK_CHG0_EN));
	nrfx_gppi_channel_endpoints_setup(ppi_chan_on_timer_match,
					  nrfx_timer_event_address_get(&app_timer_instance,
								       NRF_TIMER_EVENT_COMPARE0),
					  nrfx_gppi_task_address_get(NRFX_GPPI_TASK_CHG0_DIS));
	nrfx_gppi_fork_endpoint_setup(ppi_chan_on_timer_match,
				      nrf_egu_task_address_get(NRF_EGU0, NRF_EGU_TASK_TRIGGER0));

	return 0;
}

int controller_time_init(void)
{
	int ret;

	ret = rtc_config();
	if (ret) {
		return ret;
	}

	ret = timer_config();
	if (ret) {
		return ret;
	}

	return config_egu_trigger_on_rtc_and_timer_match();
}

static uint64_t rtc_ticks_to_us(uint32_t rtc_ticks)
{
	const uint64_t rtc_ticks_in_femto_units = 30517578125UL;

	return (rtc_ticks * rtc_ticks_in_femto_units) / 1000000000UL;
}

static uint32_t us_to_rtc_ticks(uint32_t timestamp_us)
{
	const uint64_t rtc_ticks_in_femto_units = 30517578125UL;

	return ((uint64_t)(timestamp_us) * 1000000000UL) / rtc_ticks_in_femto_units;
}

uint64_t controller_time_us_get(void)
{
	/* Simply use the RTC time here.
	 * It is possible to combine RTC and TIMER information here to get a more accurate
	 * timestamp. That requires setting up a PPI channel to capture both values simultaneously.
	 */

	const uint64_t rtc_overflow_time_us = 512000000UL;

	uint32_t captured_rtc_overflows;
	uint32_t captured_rtc_ticks;

	while (true) {
		captured_rtc_overflows = num_rtc_overflows;

		/* Read out RTC ticks after reading number of overflows. */
		barrier_isync_fence_full();

		captured_rtc_ticks = nrf_rtc_counter_get(app_rtc_instance.p_reg);

		/* Read out number of overflows after reading number of RTC ticks  */
		barrier_isync_fence_full();

		if (captured_rtc_overflows == num_rtc_overflows) {
			/* There were no new overflows after reading ticks.
			 * That is, we can use the captured value.
			 */
			break;
		}
	}

	return rtc_ticks_to_us(captured_rtc_ticks) +
	       (captured_rtc_overflows * rtc_overflow_time_us);
}

void controller_time_trigger_set(uint64_t timestamp_us)
{
	uint32_t num_overflows = timestamp_us / 512000000UL;
	uint64_t overflow_time_us = num_overflows * 512000000UL;

	uint32_t remainder_time_us = timestamp_us - overflow_time_us;
	uint32_t rtc_val = us_to_rtc_ticks(remainder_time_us);
	uint8_t timer_val = timestamp_us - rtc_ticks_to_us(rtc_val);

	/* Ensure the timer value lies between 1 and 30 so that it will
	 * always be between two RTC ticks.
	 */
	timer_val = MAX(timer_val, 1);
	timer_val = MIN(timer_val, 30);

	if (nrfx_rtc_cc_set(&app_rtc_instance, 0, rtc_val, false) != NRFX_SUCCESS) {
		printk("Failed setting trigger\n");
	}

	nrfx_timer_compare(&app_timer_instance, 0, timer_val, false);
	nrfx_gppi_channels_enable(BIT(ppi_chan_on_rtc_match));
}

uint32_t controller_time_trigger_event_addr_get(void)
{
	return nrf_egu_event_address_get(NRF_EGU0, NRF_EGU_EVENT_TRIGGERED0);
}

/* The controller time initialization must happen before
 * starting the network core.
 */
SYS_INIT(controller_time_init, POST_KERNEL, CONFIG_KERNEL_INIT_PRIORITY_DEFAULT);
```

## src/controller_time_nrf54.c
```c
/*
 * Copyright (c) 2024 Nordic Semiconductor ASA
 *
 * SPDX-License-Identifier: LicenseRef-Nordic-5-Clause
 */

/** This file implements controller time management for 54 Series devices
 */

// BK: taken from ncs/nrf/samples/bluetooth/conn_time_sync/src/controller_time_nrf54.c

#include <zephyr/kernel.h>
#include <nrfx_grtc.h>
#include "controller_time.h"

static uint8_t grtc_channel;

int controller_time_init(void)
{
	int ret;

	ret = nrfx_grtc_channel_alloc(&grtc_channel);
	if (ret != NRFX_SUCCESS) {
		printk("Failed allocating GRTC channel (ret: %d)\n",
		       ret - NRFX_ERROR_BASE_NUM);
		return -ENODEV;
	}

	nrf_grtc_sys_counter_compare_event_enable(NRF_GRTC, grtc_channel);

	return 0;
}

uint64_t controller_time_us_get(void)
{
	int ret;
	uint64_t current_time_us;

	ret = nrfx_grtc_syscounter_get(&current_time_us);
	if (ret != NRFX_SUCCESS) {
		printk("Failed obtaining system time (ret: %d)\n", ret - NRFX_ERROR_BASE_NUM);
		return 0;
	}

	return current_time_us;
}

void controller_time_trigger_set(uint64_t timestamp_us)
{
	int ret;

	nrfx_grtc_channel_t chan_data = {
		.channel = grtc_channel,
	};

	ret = nrfx_grtc_syscounter_cc_absolute_set(&chan_data, timestamp_us, false);
	if (ret != NRFX_SUCCESS) {
		printk("Failed setting CC (ret: %d)\n", ret - NRFX_ERROR_BASE_NUM);
	}
}

uint32_t controller_time_trigger_event_addr_get(void)
{
	return nrf_grtc_event_address_get(NRF_GRTC,
					  nrf_grtc_sys_counter_compare_event_get(grtc_channel));
}

SYS_INIT(controller_time_init, POST_KERNEL, CONFIG_KERNEL_INIT_PRIORITY_DEFAULT);
```
